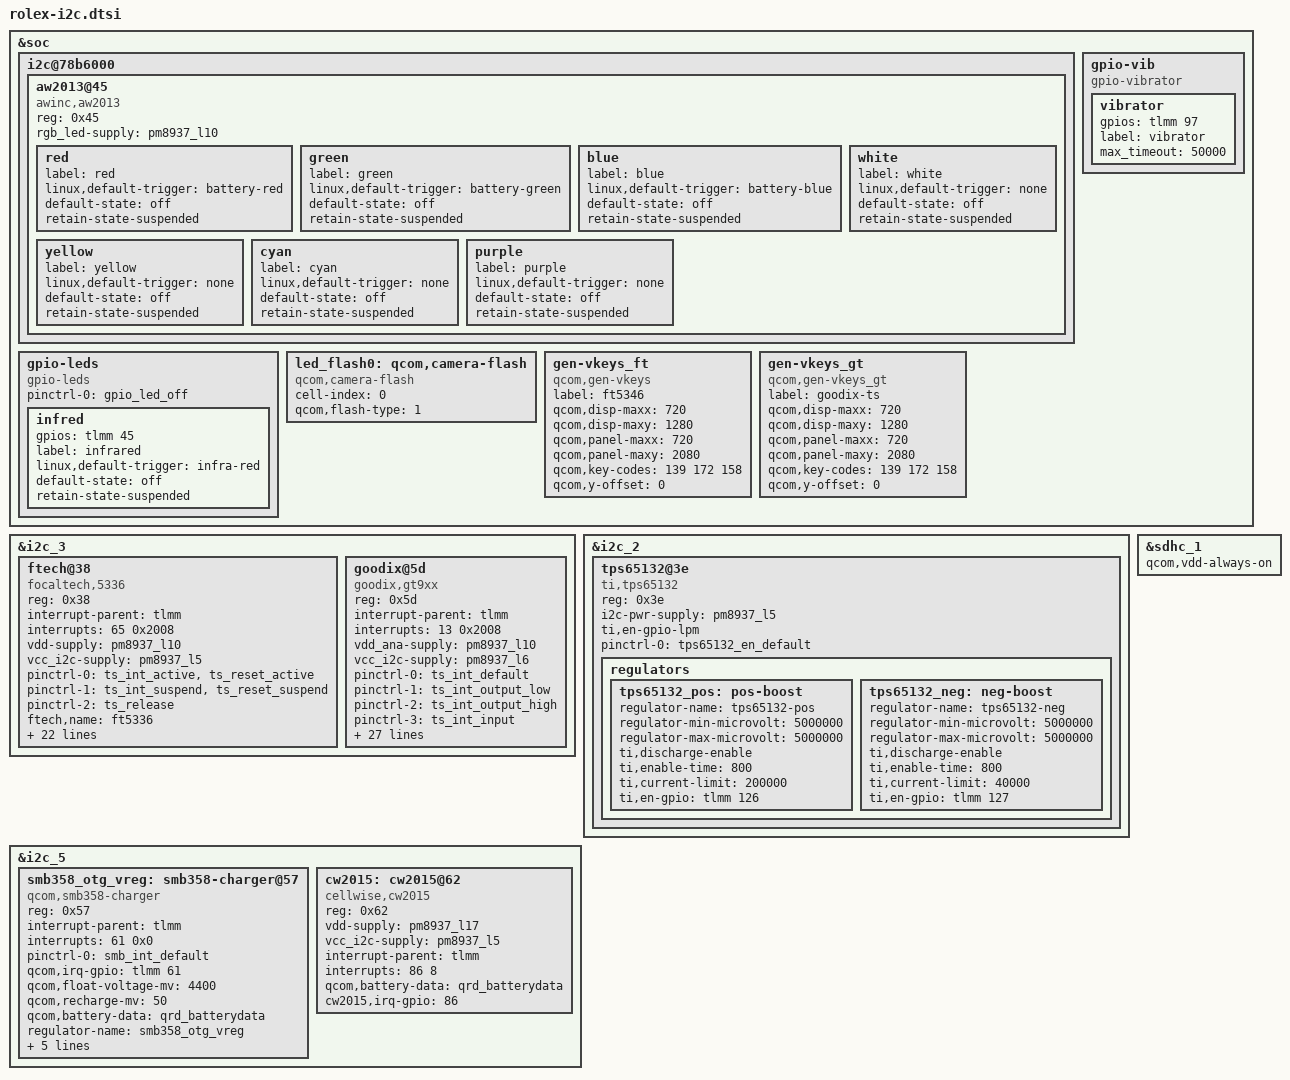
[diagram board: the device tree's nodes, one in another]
&soc {
	i2c@78b6000 { /* i2c 2 */
		aw2013@45 { /*blink */
		compatible = "awinc,aw2013";
		reg = <0x45>;
		rgb_led-supply = <&pm8937_l10>;

		red {
			label = "red";
			linux,default-trigger = "battery-red";
			default-state = "off";
			retain-state-suspended;
		};

		green {
			label = "green";
			linux,default-trigger = "battery-green";
			default-state = "off";
			retain-state-suspended;
		};

		blue {
			label = "blue";
			linux,default-trigger = "battery-blue";
			default-state = "off";
			retain-state-suspended;
		};
		white {
			label = "white";
			linux,default-trigger = "none";
			default-state = "off";
			retain-state-suspended;
		};

		yellow {
			label = "yellow";
			linux,default-trigger = "none";
			default-state = "off";
			retain-state-suspended;
		};

		cyan {
			label = "cyan";
			linux,default-trigger = "none";
			default-state = "off";
			retain-state-suspended;
		};
		purple {
			label = "purple";
			linux,default-trigger = "none";
			default-state = "off";
			retain-state-suspended;
		};

	};
};
	gpio-leds {
		compatible = "gpio-leds";
		status = "okay";
		pinctrl-names = "default";
		pinctrl-0 = <&gpio_led_off>;

			infred {
			gpios = <&tlmm 45 0>;
			label = "infrared";
			linux,default-trigger = "infra-red";
			default-state = "off";
			retain-state-suspended;
		};

	};
	gpio-vib {
		compatible = "gpio-vibrator";
		vibrator {
			gpios = <&tlmm 97 0>;
			label = "vibrator";
			max_timeout = <50000>;
		};
	};
        led_flash0: qcom,camera-flash {
		cell-index = <0>;
		compatible = "qcom,camera-flash";
		qcom,flash-type = <1>;
	};
};

&i2c_3 { /* BLSP1 QUP3 */
		status = "ok";
		ftech@38 {
			compatible = "focaltech,5336";
			reg = <0x38>;
			interrupt-parent = <&tlmm>;
			interrupts = <65 0x2008>;
			vdd-supply = <&pm8937_l10>;
			vcc_i2c-supply = <&pm8937_l5>;
			/* pins used by touchscreen */
			pinctrl-names = "pmx_ts_active","pmx_ts_suspend",
				"pmx_ts_release";
			pinctrl-0 = <&ts_int_active &ts_reset_active>;
			pinctrl-1 = <&ts_int_suspend &ts_reset_suspend>;
			pinctrl-2 = <&ts_release>;
			ftech,name = "ft5336";
			ftech,family-id = <0x36>;
			ftech,reset-gpio = <&tlmm 64 0x00>;
			ftech,irq-gpio = <&tlmm 65 0x2008>;
			ftech,display-coords = <0 0 720 1280>;
			ftech,panel-coords = <0 0 720 1280>;
			ftech,virtual-key1 = <139 140 2000>;/*menu*/
			ftech,virtual-key2 = <172 360 2000>;/*home*/
			ftech,virtual-key3 = <158 580 2000>;/*back*/
			ftech,no-force-update;
			ftech,i2c-pull-up;
			ftech,group-id = <1>;
			ftech,hard-reset-delay-ms = <20>;
			ftech,soft-reset-delay-ms = <200>;
			ftech,num-max-touches = <10>;
			ftech,fw-delay-aa-ms = <30>;
			ftech,fw-delay-55-ms = <30>;
			ftech,fw-upgrade-id1 = <0x79>;
			ftech,fw-upgrade-id2 = <0x18>;
			ftech,fw-delay-readid-ms = <10>;
			ftech,fw-delay-era-flsh-ms = <2000>;
			ftech,fw-auto-cal;
			ftech,ignore-id-check;
		};
        goodix@5d{
            compatible = "goodix,gt9xx";
            status = "okay";
            reg = <0x5d>;
            interrupt-parent = <&tlmm>;
            interrupts = <13 0x2008>;
            vdd_ana-supply = <&pm8937_l10>;
            vcc_i2c-supply = <&pm8937_l6>;
            pinctrl-names = "gdix_ts_int_default", "gdix_ts_int_output_low",
                    "gdix_ts_int_output_high", "gdix_ts_int_input",
                    "gdix_ts_rst_default", "gdix_ts_rst_output_low",
                    "gdix_ts_rst_output_high", "gdix_ts_rst_input";
            pinctrl-0 = <&ts_int_default>;
            pinctrl-1 = <&ts_int_output_low>;
            pinctrl-2 = <&ts_int_output_high>;
            pinctrl-3 = <&ts_int_input>;
            pinctrl-4 = <&ts_rst_default>;
            pinctrl-5 = <&ts_rst_output_low>;
            pinctrl-6 = <&ts_rst_output_high>;
            pinctrl-7 = <&ts_rst_input>;
            reset-gpios = <&tlmm 64 0x00>;
            irq-gpios = <&tlmm 65 0x2008>;
            irq-flags = <2>;
            touchscreen-max-id = <10>;
            touchscreen-size-x = <720>;
            touchscreen-size-y = <1280>;
            touchscreen-max-w = <1024>;
            touchscreen-max-p = <1024>;
            touchscreen-key-map = <139>, <172>,<158>;/* KEY_HOMEPAGE=172, KEY_BACK=158，KEY_MENU=139*/
            goodix,type-a-report = <0>;
            goodix,driver-send-cfg = <1>;
            goodix,wakeup-with-reset = <0>;
            goodix,resume-in-workqueue = <1>;
            goodix,int-sync = <1>;
            goodix,swap-x2y = <0>;
            goodix,esd-protect = <1>;
	    goodix,slide-wakeup = <1>;
            goodix,pen-suppress-finger = <0>;
            goodix,auto-update = <1>;
            goodix,auto-update-cfg = <0>;
            goodix,power-off-sleep = <0>;
            goodix,cfg-group0 = [
            52 D0 02 00 05 0A 3C CF 11 CF 32
            0F 5A 46 05 64 00 00 00 00 24 33
            00 14 16 28 14 87 27 CD 40 42 B8
            08 0F 0A 00 5A 33 91 00 00 00 00
            00 C4 C4 32 C8 00 31 1E 50 82 E0
            E4 0F 28 19 04 E2 21 00 97 28 00
            89 2E 00 80 3B 00 70 48 00 6E 10
            38 68 00 57 55 40 66 6F 17 3C 02
            02 00 00 00 00 00 00 02 00 00 0F
            28 00 00 00 00 00 0A 5A 00 00 00
            00 46 00 07 08 09 0A 0B 0C 0D 0E
            0F 10 11 18 17 16 15 14 13 06 05
            04 03 02 01 12 FF FF FF FF FF 29
            28 24 22 20 1F 1E 0A 08 06 05 04
            02 00 FF FF FF 00 00 00 00 00 00
            00 00 00 32 41 41 00 23 28 86 00
            00 00 00 00 00 00 0F 46 00 00 00
            00 00 00 28 4B 00 00 00 00 00 00
            00 01 01 14 78 1D 23 1E 3E 1E 01
            01 14 50 00 05 00 00 00 00 00 00
            00 00 00 00 00 00 EC 01
            ];
        };
};
&soc {
	gen-vkeys_ft {
		compatible = "qcom,gen-vkeys";
		label = "ft5346";
		qcom,disp-maxx = <720>;
		qcom,disp-maxy = <1280>;
		qcom,panel-maxx = <720>;
		qcom,panel-maxy = <2080>;
		qcom,key-codes = <139 172 158>;
		qcom,y-offset = <0>;
	};
	gen-vkeys_gt {
		compatible = "qcom,gen-vkeys_gt";
		label = "goodix-ts";
		qcom,disp-maxx = <720>;
		qcom,disp-maxy = <1280>;
		qcom,panel-maxx = <720>;
		qcom,panel-maxy = <2080>;
		qcom,key-codes = <139 172 158>;
		qcom,y-offset = <0>;
	};

};

&i2c_2 { /* i2c 2 */
	tps65132@3e {
		compatible = "ti,tps65132";
		reg = <0x3e>;
		i2c-pwr-supply = <&pm8937_l5>;
		ti,en-gpio-lpm;
		pinctrl-names = "default";
		pinctrl-0 = <&tps65132_en_default>;

		regulators {
			tps65132_pos: pos-boost {
				regulator-name = "tps65132-pos";
				regulator-min-microvolt = <5000000>;
				regulator-max-microvolt = <5000000>;
				ti,discharge-enable;
				ti,enable-time = <800>;
				ti,current-limit = <200000>;
				ti,en-gpio = <&tlmm 126 0>;
			};

			tps65132_neg: neg-boost {
				regulator-name = "tps65132-neg";
				regulator-min-microvolt = <5000000>;
				regulator-max-microvolt = <5000000>;
				ti,discharge-enable;
				ti,enable-time = <800>;
				ti,current-limit = <40000>;
				ti,en-gpio = <&tlmm 127 0>;
			};
		};
	};
};

&i2c_5 {
	status = "ok";
	smb358_otg_vreg: smb358-charger@57 {
		compatible = "qcom,smb358-charger";
		reg = <0x57>;
		interrupt-parent = <&tlmm>;
		interrupts = <61 0x0>;
		pinctrl-names = "default";
		pinctrl-0 = <&smb_int_default>;
		qcom,irq-gpio = <&tlmm 61 0x0>;
		qcom,float-voltage-mv = <4400>;
		qcom,recharge-mv = <50>;
		qcom,battery-data = <&qrd_batterydata>;
		regulator-name = "smb358_otg_vreg";
		qcom,bms-psy-name = "bms";
		qcom,chg-inhibit-disabled;	
		qcom,chg-vadc = <&pm8937_vadc>;
		qcom,iterm-ma = <150>;
		/* Optional Properties */
		qcom,thermal-mitigation = <1500 1000 700 700>;
		status = "ok";
	};
	cw2015: cw2015@62 {
		compatible = "cellwise,cw2015";
		reg = <0x62>;
		vdd-supply = <&pm8937_l17>;
		vcc_i2c-supply = <&pm8937_l5>;
		interrupt-parent = <&tlmm>;
		interrupts = <86 8>;
		qcom,battery-data = <&qrd_batterydata>;
		cw2015,irq-gpio=<86>;
	};
};
&sdhc_1 {
	qcom,vdd-always-on;
};
